VERSION ""

NS_ :

BS_:

BU_: BCA CCS BMS Motor_Controller

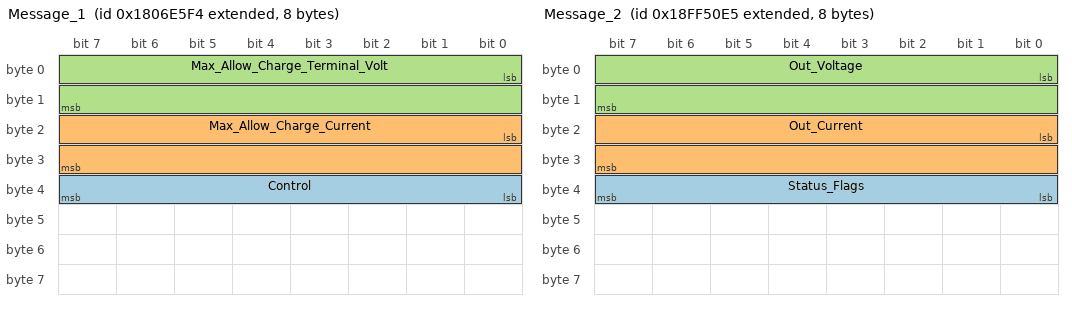
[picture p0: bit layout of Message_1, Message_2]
BO_ 2550588916 Message_1: 8 Vector__XXX
 SG_ Control : 32|8@1+ (1,0) [0|1] "" Vector__XXX
 SG_ Max_Allow_Charge_Current : 16|16@1+ (0.1,0) [0|6553.5] "A" Vector__XXX
 SG_ Max_Allow_Charge_Terminal_Volt : 0|16@1+ (0.1,0) [0|6553.5] "V" Vector__XXX

BO_ 2566869221 Message_2: 8 Vector__XXX
 SG_ Status_Flags : 32|8@1+ (1,0) [0|255] "" Vector__XXX
 SG_ Out_Current : 16|16@1+ (0.1,0) [0|6553.5] "A" Vector__XXX
 SG_ Out_Voltage : 0|16@1+ (0.1,0) [0|6553.5] "V" Vector__XXX

BA_DEF_ SG_  "SigType" ENUM  "Default","Range","RangeSigned","ASCII","Discrete","Control","ReferencePGN","DTC","StringDelimiter","StringLength","StringLengthControl","MessageCounter","MessageChecksum";
BA_DEF_ SG_  "GenSigEVName" STRING ;
BA_DEF_ SG_  "GenSigILSupport" ENUM  "No","Yes";
BA_DEF_ SG_  "GenSigSendType" ENUM  "Cyclic","OnWrite","OnWriteWithRepetition","OnChange","OnChangeWithRepetition","IfActive","IfActiveWithRepetition","NoSigSendType";
BA_DEF_ BO_  "GenMsgILSupport" ENUM  "No","Yes";
BA_DEF_ BU_  "NmStationAddress" INT 0 255;
BA_DEF_ BO_  "GenMsgSendType" ENUM  "cyclic","NotUsed","IfActive","NotUsed","NotUsed","NotUsed","NotUsed","NotUsed","noMsgSendType";
BA_DEF_ BO_  "GenMsgRequestable" INT 0 1;
BA_DEF_  "DBName" STRING ;
BA_DEF_  "BusType" STRING ;
BA_DEF_  "ProtocolType" STRING ;
BA_DEF_ BO_  "VFrameFormat" ENUM  "StandardCAN","ExtendedCAN","reserved","J1939PG";
BA_DEF_DEF_  "SigType" "Default";
BA_DEF_DEF_  "GenSigEVName" "Env@Nodename_@Signame";
BA_DEF_DEF_  "GenSigILSupport" "Yes";
BA_DEF_DEF_  "GenSigSendType" "NoSigSendType";
BA_DEF_DEF_  "GenMsgILSupport" "Yes";
BA_DEF_DEF_  "NmStationAddress" 254;
BA_DEF_DEF_  "GenMsgSendType" "noMsgSendType";
BA_DEF_DEF_  "GenMsgRequestable" 1;
BA_DEF_DEF_  "DBName" "";
BA_DEF_DEF_  "BusType" "CAN";
BA_DEF_DEF_  "ProtocolType" "J1939";
BA_DEF_DEF_  "VFrameFormat" "J1939PG";
BA_ "DBName" "Elcon";
BA_ "NmStationAddress" BU_ BCA 80;
BA_ "NmStationAddress" BU_ CCS 229;
BA_ "NmStationAddress" BU_ BMS 244;
BA_ "NmStationAddress" BU_ Motor_Controller 239;
